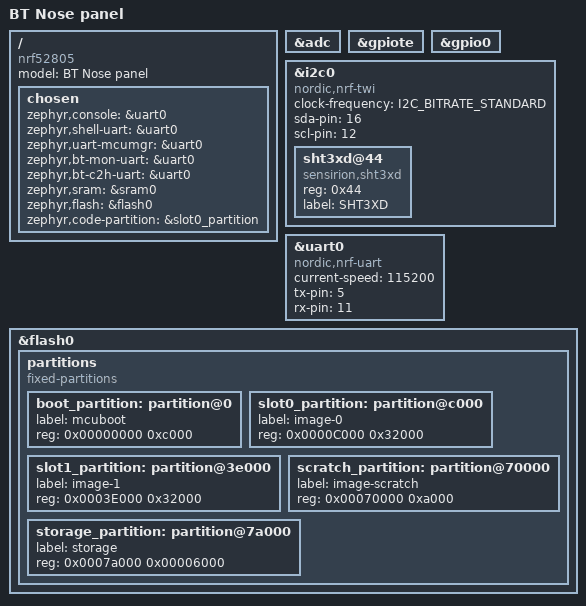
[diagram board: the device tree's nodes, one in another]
/*
 * Copyright (c) 2017 Shawn Nock <shawn@monadnock.ca>
 * Copyright (c) 2017 Linaro Limited
 *
 * SPDX-License-Identifier: Apache-2.0
 */

/dts-v1/;
#include <nordic/nrf52805_caaa.dtsi>

/ {
	model = "BT Nose panel";
	compatible = "nrf52805";

	chosen {
		zephyr,console = &uart0;
		zephyr,shell-uart = &uart0;
		zephyr,uart-mcumgr = &uart0;
		zephyr,bt-mon-uart = &uart0;
		zephyr,bt-c2h-uart = &uart0;
		zephyr,sram = &sram0;
		zephyr,flash = &flash0;
		zephyr,code-partition = &slot0_partition;
	};

};

&adc {
	status = "okay";
};

&gpiote {
	status = "okay";
};

&gpio0 {
	status = "okay";
};

&i2c0 {
	/* Cannot be used together with spi1. */
	status = "okay";
	compatible = "nordic,nrf-twi";
	clock-frequency = <I2C_BITRATE_STANDARD>;
	sda-pin = <16>;
	scl-pin = <12>;

	/*hts221@5f {
		compatible = "st,hts221";
		reg = <0x5f>;
		drdy-gpios = <&gpio0 4 0>;
		label = "HTS221";
	};*/

    sht3xd@44 {
		compatible = "sensirion,sht3xd";
		reg = <0x44>;
		label = "SHT3XD";
	};

};


&uart0 {
	status = "okay";
	compatible = "nordic,nrf-uart";
	current-speed = <115200>;
	tx-pin = <5>;
	rx-pin = <11>;
};

&flash0 {
	/*
	 * For more information, see:
	 * http://docs.zephyrproject.org/latest/guides/dts/index.html#flash-partitions
	 */
	partitions {
		compatible = "fixed-partitions";
		#address-cells = <1>;
		#size-cells = <1>;

		boot_partition: partition@0 {
			label = "mcuboot";
			reg = <0x00000000 0xc000>;
		};
		slot0_partition: partition@c000 {
			label = "image-0";
			reg = <0x0000C000 0x32000>;
		};
		slot1_partition: partition@3e000 {
			label = "image-1";
			reg = <0x0003E000 0x32000>;
		};
		scratch_partition: partition@70000 {
			label = "image-scratch";
			reg = <0x00070000 0xa000>;
		};
		storage_partition: partition@7a000 {
			label = "storage";
			reg = <0x0007a000 0x00006000>;
		};
	};
}; 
